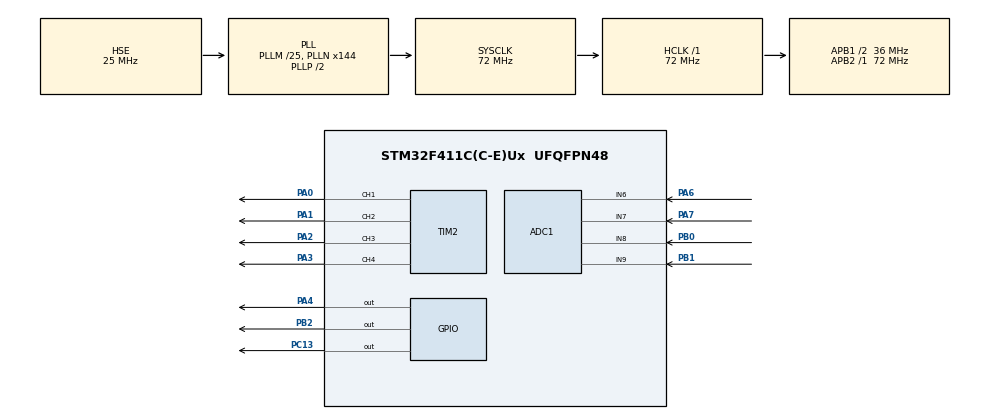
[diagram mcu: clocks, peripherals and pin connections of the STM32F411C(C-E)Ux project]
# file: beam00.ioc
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ADC1.Channel-0\#ChannelRegularConversion=ADC_CHANNEL_6
ADC1.Channel-5\#ChannelRegularConversion=ADC_CHANNEL_7
ADC1.Channel-6\#ChannelRegularConversion=ADC_CHANNEL_8
ADC1.Channel-7\#ChannelRegularConversion=ADC_CHANNEL_9
ADC1.ContinuousConvMode=ENABLE
ADC1.DMAContinuousRequests=ENABLE
ADC1.InjNumberOfConversion=0
ADC1.NbrOfConversion=4
ADC1.NbrOfConversionFlag=1
ADC1.Rank-0\#ChannelRegularConversion=1
ADC1.Rank-5\#ChannelRegularConversion=2
ADC1.Rank-6\#ChannelRegularConversion=3
ADC1.Rank-7\#ChannelRegularConversion=4
ADC1.SamplingTime-0\#ChannelRegularConversion=ADC_SAMPLETIME_144CYCLES
ADC1.SamplingTime-5\#ChannelRegularConversion=ADC_SAMPLETIME_144CYCLES
ADC1.SamplingTime-6\#ChannelRegularConversion=ADC_SAMPLETIME_144CYCLES
ADC1.SamplingTime-7\#ChannelRegularConversion=ADC_SAMPLETIME_144CYCLES
ADC1.ScanConvMode=ENABLE
ADC1.master=1
Dma.ADC1.0.Direction=DMA_PERIPH_TO_MEMORY
Dma.ADC1.0.FIFOMode=DMA_FIFOMODE_DISABLE
Dma.ADC1.0.Instance=DMA2_Stream0
Dma.ADC1.0.MemDataAlignment=DMA_MDATAALIGN_WORD
Dma.ADC1.0.MemInc=DMA_MINC_ENABLE
Dma.ADC1.0.Mode=DMA_CIRCULAR
Dma.ADC1.0.PeriphDataAlignment=DMA_PDATAALIGN_WORD
Dma.ADC1.0.PeriphInc=DMA_PINC_DISABLE
Dma.ADC1.0.Priority=DMA_PRIORITY_LOW
Dma.Request0=ADC1
Mcu.Family=STM32F4
Mcu.Name=STM32F411C(C-E)Ux
Mcu.Package=UFQFPN48
NVIC.DMA2_Stream0_IRQn=true\:0\:0\:false\:false\:true\:false\:true\:true
NVIC.PriorityGroup=NVIC_PRIORITYGROUP_4
PA0-WKUP.Signal=S_TIM2_CH1_ETR
PA1.Signal=S_TIM2_CH2
PA2.Signal=S_TIM2_CH3
PA3.Signal=S_TIM2_CH4
PA4.Signal=GPIO_Output
PA6.Signal=ADCx_IN6
PA7.Signal=ADCx_IN7
PB0.Signal=ADCx_IN8
PB1.Signal=ADCx_IN9
PB2.Signal=GPIO_Output
PC13-ANTI_TAMP.Signal=GPIO_Output
PH0\ -\ OSC_IN.Mode=HSE-External-Oscillator
PH0\ -\ OSC_IN.Signal=RCC_OSC_IN
PH1\ -\ OSC_OUT.Mode=HSE-External-Oscillator
PH1\ -\ OSC_OUT.Signal=RCC_OSC_OUT
ProjectManager.HeapSize=0x200
ProjectManager.StackSize=0x400
ProjectManager.TargetToolchain=STM32CubeIDE
RCC.48MHZClocksFreq_Value=36000000
RCC.AHBFreq_Value=72000000
RCC.APB1CLKDivider=RCC_HCLK_DIV2
RCC.APB1Freq_Value=36000000
RCC.APB1TimFreq_Value=72000000
RCC.APB2Freq_Value=72000000
RCC.APB2TimFreq_Value=72000000
RCC.CortexFreq_Value=72000000
RCC.HCLKFreq_Value=72000000
RCC.HSE_VALUE=25000000
RCC.HSI_VALUE=16000000
RCC.LSE_VALUE=32768
RCC.PLLM=25
RCC.PLLN=144
RCC.PLLSourceVirtual=RCC_PLLSOURCE_HSE
RCC.SYSCLKFreq_VALUE=72000000
RCC.SYSCLKSource=RCC_SYSCLKSOURCE_PLLCLK
RCC.VCOOutputFreq_Value=144000000
SH.ADCx_IN6.0=ADC1_IN6,IN6
SH.ADCx_IN7.0=ADC1_IN7,IN7
SH.ADCx_IN8.0=ADC1_IN8,IN8
SH.ADCx_IN9.0=ADC1_IN9,IN9
SH.S_TIM2_CH1_ETR.0=TIM2_CH1,PWM Generation1 CH1
SH.S_TIM2_CH2.0=TIM2_CH2,PWM Generation2 CH2
SH.S_TIM2_CH3.0=TIM2_CH3,PWM Generation3 CH3
SH.S_TIM2_CH4.0=TIM2_CH4,PWM Generation4 CH4
TIM2.AutoReloadPreload=TIM_AUTORELOAD_PRELOAD_ENABLE
TIM2.Channel-PWM\ Generation1\ CH1=TIM_CHANNEL_1
TIM2.Channel-PWM\ Generation2\ CH2=TIM_CHANNEL_2
TIM2.Channel-PWM\ Generation3\ CH3=TIM_CHANNEL_3
TIM2.Channel-PWM\ Generation4\ CH4=TIM_CHANNEL_4
board=custom

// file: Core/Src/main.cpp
/* USER CODE BEGIN Header */
/**
  ******************************************************************************
  * @file           : main.c
  * @brief          : Main program body
  ******************************************************************************
  * @attention
  *
  * Copyright (c) 2025 STMicroelectronics.
  * All rights reserved.
  *
  * This software is licensed under terms that can be found in the LICENSE file
  * in the root directory of this software component.
  * If no LICENSE file comes with this software, it is provided AS-IS.
  *
  ******************************************************************************
  */

/*
 * bricked board => stlink utility (windows) erase full ( with rst button)
 *
 * slow down adc ( and dma) => number of cycles
 *
 *
 */

/* USER CODE END Header */
#include "main.h"

template <int size, typename T> struct Buf {
  T buffer[size];
  unsigned int p;
  Buf() : p(0) {}
  void put(const T &t) {
    p = (p+1)%size;
    buffer[p] = t;
  }
  T last() const { return buffer[p]; }
  int length() const { return p; }
};

ADC_HandleTypeDef hadc1;
DMA_HandleTypeDef hdma_adc1;

TIM_HandleTypeDef htim2;

/* USER CODE BEGIN PV */

const int NN = 1024*10;
uint32_t AD_RES_BUFFER[NN];
/* USER CODE END PV */

void SystemClock_Config(void);
static void MX_GPIO_Init(void);
static void MX_DMA_Init(void);
static void MX_ADC1_Init(void);
static void MX_TIM2_Init(void);
/* USER CODE BEGIN PFP */

const float speed_sound_m_sec = 340.;
const float inter_like_dist = 0.1;
const int number_adc_cycles = 144;
const int mega = 1000 * 1000;
const int freq_clock = 72 * mega; // MHz
const int adc_freq_clock = freq_clock / 2; // PCLK2 divided by 2
const float T_sec = 1. / adc_freq_clock;

const float sample_rate = 1. / (T_sec * number_adc_cycles * 4) * 4;
const float T_sample = 1. / sample_rate;
const float dist = 0.1;
const float duration_dist = dist / speed_sound_m_sec;
const float n_samples = duration_dist / T_sample;
const int n_samples_i = (int)n_samples;
Buf<n_samples_i*3, int> buf3;
Buf<n_samples_i*2, int> buf2;
Buf<n_samples_i, int> buf1;
Buf<n_samples_i, int> buf_out;

long int  a = 0;
GPIO_PinState bvalue;
long int b = 0;

void HAL_ADC_ConvCpltCallback(ADC_HandleTypeDef* hadc)
{
    // Conversion Complete & DMA Transfer Complete As Well
    // So The AD_RES_BUFFER Is Now Updated & Let's Move Values To The PWM CCRx
    // Update The PWM Channels With Latest ADC Scan Conversion Results
	/*
    TIM2->CCR1 = (AD_RES_BUFFER[0] << 4);  // ADC CH6 -> PWM CH1
    TIM2->CCR2 = (AD_RES_BUFFER[1] << 4);  // ADC CH7 -> PWM CH2
    TIM2->CCR3 = (AD_RES_BUFFER[2] << 4);  // ADC CH8 -> PWM CH3
    TIM2->CCR4 = (AD_RES_BUFFER[3] << 4);  // ADC CH9 -> PWM CH4
    */
    a ++;
    bvalue = (GPIO_PinState)(a%2);
    HAL_GPIO_WritePin(GPIOA, GPIO_PIN_4, bvalue);

    for (int i = 0; i < NN; i+=4) {
    	buf3.put(AD_RES_BUFFER[i+3]);
    	buf2.put(AD_RES_BUFFER[i+2]);
    	buf1.put(AD_RES_BUFFER[i+1]);
    	int g = (AD_RES_BUFFER[i] + buf3.last() + buf2.last() + buf1.last())/4;
    	buf_out.put(g);
    }

}
/* USER CODE END PFP */

int main(void)
{

  /* USER CODE BEGIN 1 */
	// bizarre : je dois x4

  /* USER CODE END 1 */

  /* MCU Configuration--------------------------------------------------------*/

  /* Reset of all peripherals, Initializes the Flash interface and the Systick. */
  HAL_Init();

  /* Configure the system clock */
  SystemClock_Config();

  /* Initialize all configured peripherals */
  MX_GPIO_Init();
  MX_DMA_Init();
  MX_ADC1_Init();
  MX_TIM2_Init();
  /* USER CODE BEGIN 2 */
  HAL_ADC_Start_DMA(&hadc1, AD_RES_BUFFER, NN);
  /* USER CODE END 2 */

  /* Infinite loop */
  /* USER CODE BEGIN WHILE */
  while (1)
  {
	  int v = AD_RES_BUFFER[0]/10;
	  b++;
	  if (1) {
		  HAL_GPIO_WritePin(GPIOC, GPIO_PIN_13, (GPIO_PinState)0);
		  HAL_Delay(v);
		  HAL_GPIO_WritePin(GPIOC, GPIO_PIN_13, (GPIO_PinState)1);
		  HAL_Delay(v);
	  }
	  b++;
    /* USER CODE END WHILE */

  }
}

void SystemClock_Config(void)
{
  RCC_OscInitTypeDef RCC_OscInitStruct = {0};
  RCC_ClkInitTypeDef RCC_ClkInitStruct = {0};

  /** Configure the main internal regulator output voltage
  */
  __HAL_RCC_PWR_CLK_ENABLE();
  __HAL_PWR_VOLTAGESCALING_CONFIG(PWR_REGULATOR_VOLTAGE_SCALE1);

  /** Initializes the RCC Oscillators according to the specified parameters
  * in the RCC_OscInitTypeDef structure.
  */
  RCC_OscInitStruct.OscillatorType = RCC_OSCILLATORTYPE_HSE;
  RCC_OscInitStruct.HSEState = RCC_HSE_ON;
  RCC_OscInitStruct.PLL.PLLState = RCC_PLL_ON;
  RCC_OscInitStruct.PLL.PLLSource = RCC_PLLSOURCE_HSE;
  RCC_OscInitStruct.PLL.PLLM = 25;
  RCC_OscInitStruct.PLL.PLLN = 144;
  RCC_OscInitStruct.PLL.PLLP = RCC_PLLP_DIV2;
  RCC_OscInitStruct.PLL.PLLQ = 4;
  if (HAL_RCC_OscConfig(&RCC_OscInitStruct) != HAL_OK)
  {
    Error_Handler();
  }

  /** Initializes the CPU, AHB and APB buses clocks
  */
  RCC_ClkInitStruct.ClockType = RCC_CLOCKTYPE_HCLK|RCC_CLOCKTYPE_SYSCLK
                              |RCC_CLOCKTYPE_PCLK1|RCC_CLOCKTYPE_PCLK2;
  RCC_ClkInitStruct.SYSCLKSource = RCC_SYSCLKSOURCE_PLLCLK;
  RCC_ClkInitStruct.AHBCLKDivider = RCC_SYSCLK_DIV1;
  RCC_ClkInitStruct.APB1CLKDivider = RCC_HCLK_DIV2;
  RCC_ClkInitStruct.APB2CLKDivider = RCC_HCLK_DIV1;

  if (HAL_RCC_ClockConfig(&RCC_ClkInitStruct, FLASH_LATENCY_2) != HAL_OK)
  {
    Error_Handler();
  }
}

static void MX_ADC1_Init(void)
{

  ADC_ChannelConfTypeDef sConfig = {0};

  /** Configure the global features of the ADC (Clock, Resolution, Data Alignment and number of conversion)
  */
  hadc1.Instance = ADC1;
  hadc1.Init.ClockPrescaler = ADC_CLOCK_SYNC_PCLK_DIV2;
  hadc1.Init.Resolution = ADC_RESOLUTION_12B;
  hadc1.Init.ScanConvMode = ENABLE;
  hadc1.Init.ContinuousConvMode = ENABLE;
  hadc1.Init.DiscontinuousConvMode = DISABLE;
  hadc1.Init.ExternalTrigConvEdge = ADC_EXTERNALTRIGCONVEDGE_NONE;
  hadc1.Init.ExternalTrigConv = ADC_SOFTWARE_START;
  hadc1.Init.DataAlign = ADC_DATAALIGN_RIGHT;
  hadc1.Init.NbrOfConversion = 4;
  hadc1.Init.DMAContinuousRequests = ENABLE;
  hadc1.Init.EOCSelection = ADC_EOC_SINGLE_CONV;
  if (HAL_ADC_Init(&hadc1) != HAL_OK)
  {
    Error_Handler();
  }

  /** Configure for the selected ADC regular channel its corresponding rank in the sequencer and its sample time.
  */
  sConfig.Channel = ADC_CHANNEL_6;
  sConfig.Rank = 1;
  sConfig.SamplingTime = ADC_SAMPLETIME_144CYCLES;
  if (HAL_ADC_ConfigChannel(&hadc1, &sConfig) != HAL_OK)
  {
    Error_Handler();
  }

  /** Configure for the selected ADC regular channel its corresponding rank in the sequencer and its sample time.
  */
  sConfig.Channel = ADC_CHANNEL_7;
  sConfig.Rank = 2;
  if (HAL_ADC_ConfigChannel(&hadc1, &sConfig) != HAL_OK)
  {
    Error_Handler();
  }

  /** Configure for the selected ADC regular channel its corresponding rank in the sequencer and its sample time.
  */
  sConfig.Channel = ADC_CHANNEL_8;
  sConfig.Rank = 3;
  if (HAL_ADC_ConfigChannel(&hadc1, &sConfig) != HAL_OK)
  {
    Error_Handler();
  }

  /** Configure for the selected ADC regular channel its corresponding rank in the sequencer and its sample time.
  */
  sConfig.Channel = ADC_CHANNEL_9;
  sConfig.Rank = 4;
  if (HAL_ADC_ConfigChannel(&hadc1, &sConfig) != HAL_OK)
  {
    Error_Handler();
  }

}

static void MX_TIM2_Init(void)
{

  TIM_MasterConfigTypeDef sMasterConfig = {0};
  TIM_OC_InitTypeDef sConfigOC = {0};

  htim2.Instance = TIM2;
  htim2.Init.Prescaler = 0;
  htim2.Init.CounterMode = TIM_COUNTERMODE_UP;
  htim2.Init.Period = 4294967295;
  htim2.Init.ClockDivision = TIM_CLOCKDIVISION_DIV1;
  htim2.Init.AutoReloadPreload = TIM_AUTORELOAD_PRELOAD_ENABLE;
  if (HAL_TIM_PWM_Init(&htim2) != HAL_OK)
  {
    Error_Handler();
  }
  sMasterConfig.MasterOutputTrigger = TIM_TRGO_RESET;
  sMasterConfig.MasterSlaveMode = TIM_MASTERSLAVEMODE_DISABLE;
  if (HAL_TIMEx_MasterConfigSynchronization(&htim2, &sMasterConfig) != HAL_OK)
  {
    Error_Handler();
  }
  sConfigOC.OCMode = TIM_OCMODE_PWM1;
  sConfigOC.Pulse = 0;
  sConfigOC.OCPolarity = TIM_OCPOLARITY_HIGH;
  sConfigOC.OCFastMode = TIM_OCFAST_DISABLE;
  if (HAL_TIM_PWM_ConfigChannel(&htim2, &sConfigOC, TIM_CHANNEL_1) != HAL_OK)
  {
    Error_Handler();
  }
  if (HAL_TIM_PWM_ConfigChannel(&htim2, &sConfigOC, TIM_CHANNEL_2) != HAL_OK)
  {
    Error_Handler();
  }
  if (HAL_TIM_PWM_ConfigChannel(&htim2, &sConfigOC, TIM_CHANNEL_3) != HAL_OK)
  {
    Error_Handler();
  }
  if (HAL_TIM_PWM_ConfigChannel(&htim2, &sConfigOC, TIM_CHANNEL_4) != HAL_OK)
  {
    Error_Handler();
  }
  HAL_TIM_MspPostInit(&htim2);

}

static void MX_DMA_Init(void)
{

  /* DMA controller clock enable */
  __HAL_RCC_DMA2_CLK_ENABLE();

  /* DMA interrupt init */
  /* DMA2_Stream0_IRQn interrupt configuration */
  HAL_NVIC_SetPriority(DMA2_Stream0_IRQn, 0, 0);
  HAL_NVIC_EnableIRQ(DMA2_Stream0_IRQn);

}

static void MX_GPIO_Init(void)
{
  GPIO_InitTypeDef GPIO_InitStruct = {0};

  /* GPIO Ports Clock Enable */
  __HAL_RCC_GPIOC_CLK_ENABLE();
  __HAL_RCC_GPIOH_CLK_ENABLE();
  __HAL_RCC_GPIOA_CLK_ENABLE();
  __HAL_RCC_GPIOB_CLK_ENABLE();

  /*Configure GPIO pin Output Level */
  HAL_GPIO_WritePin(GPIOC, GPIO_PIN_13, GPIO_PIN_SET);

  /*Configure GPIO pin Output Level */
  HAL_GPIO_WritePin(GPIOA, GPIO_PIN_5, GPIO_PIN_RESET);

  /*Configure GPIO pin Output Level */
  HAL_GPIO_WritePin(GPIOB, GPIO_PIN_2, GPIO_PIN_RESET);

  /*Configure GPIO pin : PC13 */
  GPIO_InitStruct.Pin = GPIO_PIN_13;
  GPIO_InitStruct.Mode = GPIO_MODE_OUTPUT_PP;
  GPIO_InitStruct.Pull = GPIO_NOPULL;
  GPIO_InitStruct.Speed = GPIO_SPEED_FREQ_LOW;
  HAL_GPIO_Init(GPIOC, &GPIO_InitStruct);

  /*Configure GPIO pin : PA5 */
  GPIO_InitStruct.Pin = GPIO_PIN_5;
  GPIO_InitStruct.Mode = GPIO_MODE_OUTPUT_PP;
  GPIO_InitStruct.Pull = GPIO_NOPULL;
  GPIO_InitStruct.Speed = GPIO_SPEED_FREQ_LOW;
  HAL_GPIO_Init(GPIOA, &GPIO_InitStruct);

  /*Configure GPIO pin : PB2 */
  GPIO_InitStruct.Pin = GPIO_PIN_2;
  GPIO_InitStruct.Mode = GPIO_MODE_OUTPUT_PP;
  GPIO_InitStruct.Pull = GPIO_NOPULL;
  GPIO_InitStruct.Speed = GPIO_SPEED_FREQ_LOW;
  HAL_GPIO_Init(GPIOB, &GPIO_InitStruct);

}

void Error_Handler(void)
{
  __disable_irq();
  while (1)
  {
  }
}
